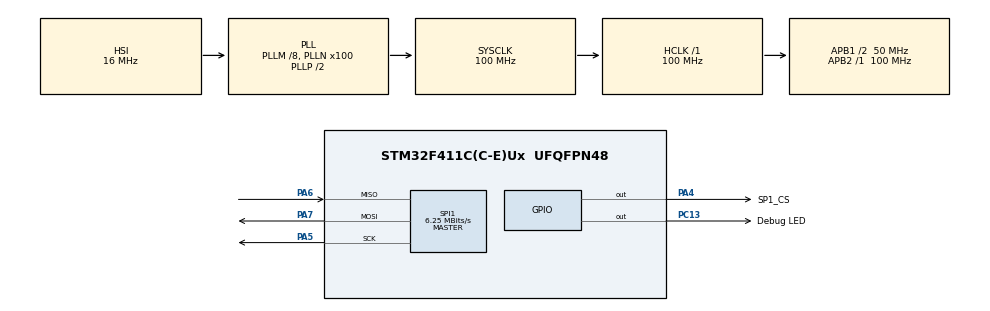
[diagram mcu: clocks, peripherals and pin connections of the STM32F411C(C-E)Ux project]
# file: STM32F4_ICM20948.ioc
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Mcu.Family=STM32F4
Mcu.Name=STM32F411C(C-E)Ux
Mcu.Package=UFQFPN48
NVIC.PriorityGroup=NVIC_PRIORITYGROUP_4
PA13.Mode=Serial_Wire
PA13.Signal=SYS_JTMS-SWDIO
PA14.Mode=Serial_Wire
PA14.Signal=SYS_JTCK-SWCLK
PA4.GPIO_Label=SP1_CS
PA4.PinState=GPIO_PIN_SET
PA4.Signal=GPIO_Output
PA5.Mode=Full_Duplex_Master
PA5.Signal=SPI1_SCK
PA6.Mode=Full_Duplex_Master
PA6.Signal=SPI1_MISO
PA7.Mode=Full_Duplex_Master
PA7.Signal=SPI1_MOSI
PC13-ANTI_TAMP.GPIO_Label=Debug LED
PC13-ANTI_TAMP.PinState=GPIO_PIN_SET
PC13-ANTI_TAMP.Signal=GPIO_Output
ProjectManager.HeapSize=0x200
ProjectManager.StackSize=0x400
ProjectManager.TargetToolchain=STM32CubeIDE
RCC.48MHZClocksFreq_Value=50000000
RCC.AHBFreq_Value=100000000
RCC.APB1CLKDivider=RCC_HCLK_DIV2
RCC.APB1Freq_Value=50000000
RCC.APB1TimFreq_Value=100000000
RCC.APB2Freq_Value=100000000
RCC.APB2TimFreq_Value=100000000
RCC.CortexFreq_Value=100000000
RCC.HCLKFreq_Value=100000000
RCC.HSE_VALUE=25000000
RCC.HSI_VALUE=16000000
RCC.LSE_VALUE=32768
RCC.PLLM=8
RCC.PLLN=100
RCC.SYSCLKFreq_VALUE=100000000
RCC.SYSCLKSource=RCC_SYSCLKSOURCE_PLLCLK
RCC.VCOOutputFreq_Value=200000000
SPI1.BaudRatePrescaler=SPI_BAUDRATEPRESCALER_16
SPI1.CLKPhase=SPI_PHASE_2EDGE
SPI1.CLKPolarity=SPI_POLARITY_HIGH
SPI1.CalculateBaudRate=6.25 MBits/s
SPI1.Direction=SPI_DIRECTION_2LINES
SPI1.Mode=SPI_MODE_MASTER
SPI1.VirtualType=VM_MASTER
board=custom

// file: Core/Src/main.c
/* USER CODE BEGIN Header */
/**
  ******************************************************************************
  * @file           : main.c
  * @brief          : Main program body
  ******************************************************************************
  * @attention
  *
  * <h2><center>&copy; Copyright (c) 2020 STMicroelectronics.
  * All rights reserved.</center></h2>
  *
  * This software component is licensed by ST under BSD 3-Clause license,
  * the "License"; You may not use this file except in compliance with the
  * License. You may obtain a copy of the License at:
  *                        opensource.org/licenses/BSD-3-Clause
  *
  ******************************************************************************
  */
/* USER CODE END Header */
#include "main.h"
#include "spi.h"
#include "gpio.h"

/* USER CODE BEGIN Includes */
#include "mokhwa_ICM20948.h"
/* USER CODE END Includes */

/* USER CODE BEGIN PV */

ICM20948_DATA MYDATA;
uint8_t whoami_icm;
uint8_t whoami_mag;

/* USER CODE END PV */

void SystemClock_Config(void);

int main(void)
{

  /* MCU Configuration--------------------------------------------------------*/

  /* Reset of all peripherals, Initializes the Flash interface and the Systick. */
	HAL_Init();

  /* Configure the system clock */
  SystemClock_Config();

  /* Initialize all configured peripherals */
  MX_GPIO_Init();
  MX_SPI1_Init();
  /* USER CODE BEGIN 2 */

  INIT_ICM20948();
  INIT_AK09916();

  if(WHOAMI_AK09916() == DEVICE_ID_AK09916)
  	  HAL_GPIO_WritePin(Debug_LED_GPIO_Port, Debug_LED_Pin, RESET);	// Debug LED

  //whoami_mag = WHOAMI_AK09916();

  //WHOAMI_AK09916_1();

  //whoami_icm = WHOAMI_ICM20948();
  //whoami_mag = WHOAMI_AK09916();
  //READ_MAG(&MYDATA);

  /* USER CODE END 2 */

  /* Infinite loop */
  while (1)
  {

	  READ_GYRO(&MYDATA);
	  READ_ACCEL(&MYDATA);
	  READ_MAG(&MYDATA);

  }
}

void SystemClock_Config(void)
{
  RCC_OscInitTypeDef RCC_OscInitStruct = {0};
  RCC_ClkInitTypeDef RCC_ClkInitStruct = {0};

  /** Configure the main internal regulator output voltage
  */
  __HAL_RCC_PWR_CLK_ENABLE();
  __HAL_PWR_VOLTAGESCALING_CONFIG(PWR_REGULATOR_VOLTAGE_SCALE1);
  /** Initializes the RCC Oscillators according to the specified parameters
  * in the RCC_OscInitTypeDef structure.
  */
  RCC_OscInitStruct.OscillatorType = RCC_OSCILLATORTYPE_HSI;
  RCC_OscInitStruct.HSIState = RCC_HSI_ON;
  RCC_OscInitStruct.HSICalibrationValue = RCC_HSICALIBRATION_DEFAULT;
  RCC_OscInitStruct.PLL.PLLState = RCC_PLL_ON;
  RCC_OscInitStruct.PLL.PLLSource = RCC_PLLSOURCE_HSI;
  RCC_OscInitStruct.PLL.PLLM = 8;
  RCC_OscInitStruct.PLL.PLLN = 100;
  RCC_OscInitStruct.PLL.PLLP = RCC_PLLP_DIV2;
  RCC_OscInitStruct.PLL.PLLQ = 4;
  if (HAL_RCC_OscConfig(&RCC_OscInitStruct) != HAL_OK)
  {
    Error_Handler();
  }
  /** Initializes the CPU, AHB and APB buses clocks
  */
  RCC_ClkInitStruct.ClockType = RCC_CLOCKTYPE_HCLK|RCC_CLOCKTYPE_SYSCLK
                              |RCC_CLOCKTYPE_PCLK1|RCC_CLOCKTYPE_PCLK2;
  RCC_ClkInitStruct.SYSCLKSource = RCC_SYSCLKSOURCE_PLLCLK;
  RCC_ClkInitStruct.AHBCLKDivider = RCC_SYSCLK_DIV1;
  RCC_ClkInitStruct.APB1CLKDivider = RCC_HCLK_DIV2;
  RCC_ClkInitStruct.APB2CLKDivider = RCC_HCLK_DIV1;

  if (HAL_RCC_ClockConfig(&RCC_ClkInitStruct, FLASH_LATENCY_3) != HAL_OK)
  {
    Error_Handler();
  }
}

void Error_Handler(void)
{
  __disable_irq();
  while (1)
  {
  }
}

/************************ (C) COPYRIGHT STMicroelectronics *****END OF FILE****/
